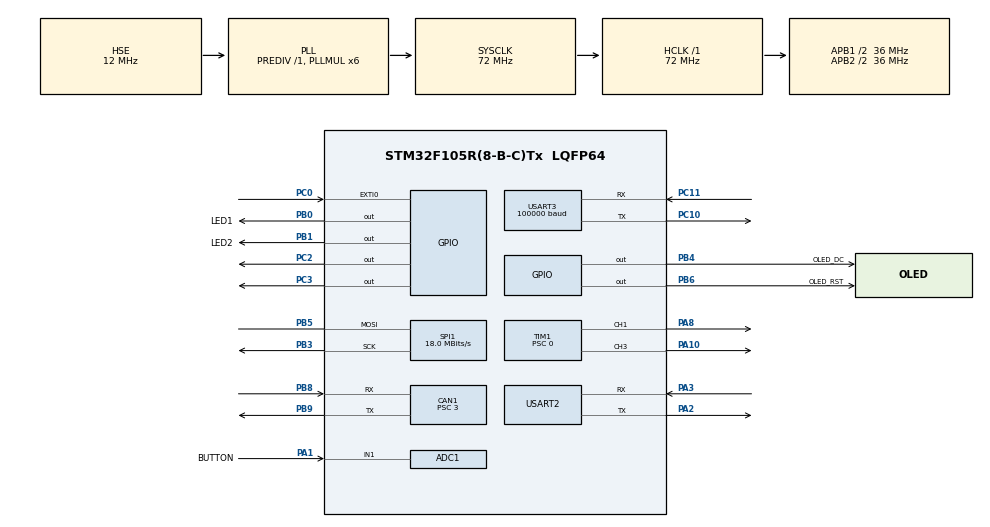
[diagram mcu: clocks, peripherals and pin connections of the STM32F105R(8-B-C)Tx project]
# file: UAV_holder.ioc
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Mcu.Family=STM32F1
NVIC.USART3_IRQn=true\:6\:0\:true\:true\:true\:1\:true\:true\:true
Dma.USART3_RX.1.Mode=DMA_CIRCULAR
SPI1.VirtualType=VM_MASTER
Dma.TIM1_CH3.3.MemDataAlignment=DMA_MDATAALIGN_HALFWORD
PC10.Signal=USART3_TX
PB0.GPIO_Label=LED1
PB6.GPIO_Label=OLED_RST
PC2.GPIO_Speed=GPIO_SPEED_FREQ_HIGH
Dma.TIM1_CH3.3.Direction=DMA_MEMORY_TO_PERIPH
PC3.GPIO_Speed=GPIO_SPEED_FREQ_HIGH
RCC.SYSCLKSource=RCC_SYSCLKSOURCE_PLLCLK
ProjectManager.StackSize=0x400
PC3.PinState=GPIO_PIN_SET
PD1-OSC_OUT.Signal=RCC_OSC_OUT
NVIC.DMA1_Channel3_IRQn=true\:6\:0\:true\:false\:true\:true\:false\:true
TIM1.Prescaler=0
Dma.USART3_RX.1.MemInc=DMA_MINC_ENABLE
USART3.BaudRate=100000
Dma.TIM1_CH1.2.Direction=DMA_MEMORY_TO_PERIPH
Dma.USART3_RX.1.Instance=DMA1_Channel3
PB0.PinState=GPIO_PIN_SET
NVIC.CAN1_TX_IRQn=true\:6\:0\:true\:false\:true\:true\:true\:true
FREERTOS.configUSE_STATS_FORMATTING_FUNCTIONS=1
SPI1.Direction=SPI_DIRECTION_1LINE
RCC.HCLKFreq_Value=72000000
RCC.APB2TimFreq_Value=72000000
PB6.Signal=GPIO_Output
Dma.ADC1.0.Direction=DMA_PERIPH_TO_MEMORY
Dma.USART3_RX.1.PeriphDataAlignment=DMA_PDATAALIGN_BYTE
SPI1.CalculateBaudRate=18.0 MBits/s
PC3.Signal=GPIO_Output
Dma.ADC1.0.MemDataAlignment=DMA_MDATAALIGN_HALFWORD
RCC.AHBFreq_Value=72000000
ADC1.Channel-0\#ChannelRegularConversion=ADC_CHANNEL_1
RCC.HSE_VALUE=12000000
PB3.Mode=Simplex_Bidirectional_Master
RCC.PLLMUL=RCC_PLL_MUL6
Dma.TIM1_CH3.3.Mode=DMA_NORMAL
Dma.USART3_RX.1.Priority=DMA_PRIORITY_LOW
TIM1.Channel-PWM\ Generation1\ CH1=TIM_CHANNEL_1
PA14.Mode=Serial_Wire
Dma.TIM1_CH1.2.Mode=DMA_NORMAL
Dma.ADC1.0.PeriphInc=DMA_PINC_DISABLE
PB1.GPIO_Label=LED2
PB5.Mode=Simplex_Bidirectional_Master
PA8.Signal=S_TIM1_CH1
TIM6.Period=65535
VP_FREERTOS_VS_CMSIS_V1.Mode=CMSIS_V1
ADC1.SamplingTime-0\#ChannelRegularConversion=ADC_SAMPLETIME_1CYCLE_5
PB1.PinState=GPIO_PIN_SET
CAN1.Prescaler=3
PB9.Signal=CAN1_TX
Mcu.Package=LQFP64
PB1.Signal=GPIO_Output
NVIC.TimeBase=TIM7_IRQn
USART2.VirtualMode=VM_ASYNC
Dma.USART3_RX.1.Direction=DMA_PERIPH_TO_MEMORY
NVIC.TimeBaseIP=TIM7
PA10.Signal=S_TIM1_CH3
PC11.Mode=Asynchronous
RCC.APB2CLKDivider=RCC_HCLK_DIV2
SH.ADCx_IN1.0=ADC1_IN1,IN1
Dma.Request2=TIM1_CH1
Dma.Request1=USART3_RX
RCC.APB1TimFreq_Value=72000000
FREERTOS.configGENERATE_RUN_TIME_STATS=1
Dma.Request3=TIM1_CH3
TIM1.Period=90-1
Dma.Request0=ADC1
CAN1.CalculateTimeBit=999.99
Dma.TIM1_CH1.2.Priority=DMA_PRIORITY_LOW
NVIC.TIM7_IRQn=true\:0\:0\:false\:false\:true\:false\:false\:true
Dma.TIM1_CH1.2.MemInc=DMA_MINC_ENABLE
Dma.TIM1_CH1.2.PeriphDataAlignment=DMA_PDATAALIGN_HALFWORD
PB4.Signal=GPIO_Output
PA3.Signal=USART2_RX
CAN1.CalculateTimeQuantum=83.33333333333334
RCC.PLLSourceVirtual=RCC_PLLSOURCE_HSE
NVIC.DMA1_Channel6_IRQn=true\:5\:0\:false\:false\:true\:true\:false\:true
Dma.TIM1_CH3.3.Priority=DMA_PRIORITY_LOW
Dma.ADC1.0.Instance=DMA1_Channel1
FREERTOS.Tasks01=defaultTask,0,128,StartDefaultTask,Default,NULL
ADC1.Rank-0\#ChannelRegularConversion=1
PD1-OSC_OUT.Mode=HSE-External-Oscillator
Dma.TIM1_CH1.2.PeriphInc=DMA_PINC_DISABLE
PC11.Signal=USART3_RX
VP_SYS_VS_tim7.Mode=TIM7
CAN1.CalculateBaudRate=1000000
TIM6.Prescaler=72-1
PC2.Signal=GPIO_Output
PC10.Mode=Asynchronous
VP_TIM6_VS_ClockSourceINT.Mode=Enable_Timer
Dma.USART3_RX.1.MemDataAlignment=DMA_MDATAALIGN_BYTE
PD0-OSC_IN.Signal=RCC_OSC_IN
Dma.TIM1_CH1.2.MemDataAlignment=DMA_MDATAALIGN_HALFWORD
PC0.Signal=GPXTI0
RCC.APB1CLKDivider=RCC_HCLK_DIV2
NVIC.TIM6_IRQn=true\:6\:0\:true\:false\:true\:true\:true\:true
RCC.ADCPresc=RCC_ADCPCLK2_DIV4
Dma.TIM1_CH1.2.Instance=DMA1_Channel2
PA13.Signal=SYS_JTMS-SWDIO
PA3.Mode=Asynchronous
Dma.ADC1.0.PeriphDataAlignment=DMA_PDATAALIGN_HALFWORD
Dma.TIM1_CH3.3.PeriphInc=DMA_PINC_DISABLE
SH.S_TIM1_CH1.0=TIM1_CH1,PWM Generation1 CH1
CAN1.BS2=CAN_BS2_4TQ
CAN1.BS1=CAN_BS1_7TQ
NVIC.DMA1_Channel2_IRQn=true\:5\:0\:false\:false\:true\:true\:false\:true
ProjectManager.TargetToolchain=MDK-ARM V5
FREERTOS.configUSE_TRACE_FACILITY=1
Dma.ADC1.0.Mode=DMA_NORMAL
PB9.Mode=CAN_Activate
Dma.ADC1.0.Priority=DMA_PRIORITY_LOW
Dma.TIM1_CH3.3.MemInc=DMA_MINC_ENABLE
RCC.USBFreq_Value=48000000
PA1.Signal=ADCx_IN1
PD0-OSC_IN.Mode=HSE-External-Oscillator
board=custom
RCC.APB2Freq_Value=36000000
PB4.GPIO_Label=OLED_DC
SPI1.Mode=SPI_MODE_MASTER
Dma.TIM1_CH3.3.Instance=DMA1_Channel6
PA1.GPIO_Label=BUTTON
PC2.GPIO_PuPd=GPIO_PULLUP
PA13.Mode=Serial_Wire
Mcu.Name=STM32F105R(8-B-C)Tx
PA2.Signal=USART2_TX
PB3.Signal=SPI1_SCK
RCC.SYSCLKFreq_VALUE=72000000
PB5.Signal=SPI1_MOSI
ADC1.master=1
PC2.PinState=GPIO_PIN_SET
USART3.VirtualMode=VM_ASYNC
PA14.Signal=SYS_JTCK-SWCLK
Dma.ADC1.0.MemInc=DMA_MINC_ENABLE
ProjectManager.HeapSize=0x200
SH.S_TIM1_CH3.0=TIM1_CH3,PWM Generation3 CH3
NVIC.PriorityGroup=NVIC_PRIORITYGROUP_4
ADC1.NbrOfConversionFlag=1
PB8.Mode=CAN_Activate
PB8.Signal=CAN1_RX
PA2.Mode=Asynchronous
Dma.TIM1_CH3.3.PeriphDataAlignment=DMA_PDATAALIGN_HALFWORD
NVIC.DMA1_Channel1_IRQn=true\:6\:0\:true\:false\:true\:true\:false\:true
TIM1.Channel-PWM\ Generation3\ CH3=TIM_CHANNEL_3
RCC.APB1Freq_Value=36000000
PB0.Signal=GPIO_Output
NVIC.CAN1_RX0_IRQn=true\:6\:0\:true\:false\:true\:true\:true\:true
Dma.USART3_RX.1.PeriphInc=DMA_PINC_DISABLE
PC3.GPIO_PuPd=GPIO_PULLUP

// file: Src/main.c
/* USER CODE BEGIN Header */
/**
  ******************************************************************************
  * @file           : main.c
  * @brief          : Main program body
  ******************************************************************************
  * @attention
  *
  * <h2><center>&copy; Copyright (c) 2019 STMicroelectronics.
  * All rights reserved.</center></h2>
  *
  * This software component is licensed by ST under Ultimate Liberty license
  * SLA0044, the "License"; You may not use this file except in compliance with
  * the License. You may obtain a copy of the License at:
  *                             www.st.com/SLA0044
  *
  ******************************************************************************
  */
/* USER CODE END Header */
#include "main.h"
#include "cmsis_os.h"
#include "adc.h"
#include "can.h"
#include "dma.h"
#include "spi.h"
#include "tim.h"
#include "usart.h"
#include "gpio.h"

/* USER CODE BEGIN Includes */
#include "bsp_can.h"
#include "Remote_Control.h"
#include "pid.h"
#include "Init.h"

/* USER CODE END Includes */

void SystemClock_Config(void);
void MX_FREERTOS_Init(void);
static void MX_NVIC_Init(void);

int main(void)
{

  /* MCU Configuration--------------------------------------------------------*/

  /* Reset of all peripherals, Initializes the Flash interface and the Systick. */
  HAL_Init();

  /* USER CODE BEGIN Init */
//extern volatile unsigned long long FreeRTOSRunTimeTicks;
  /* USER CODE END Init */

  /* Configure the system clock */
  SystemClock_Config();

  /* Initialize all configured peripherals */
  MX_GPIO_Init();
  MX_DMA_Init();
  MX_USART2_UART_Init();
  MX_ADC1_Init();
  MX_SPI1_Init();
  MX_USART3_UART_Init();
  MX_CAN1_Init();
  MX_TIM6_Init();
  MX_TIM1_Init();

  /* Initialize interrupts */
  MX_NVIC_Init();
  /* USER CODE BEGIN 2 */
	 User_Init();
	 Task_Init();
  /* USER CODE END 2 */

  /* Call init function for freertos objects (in freertos.c) */
  MX_FREERTOS_Init();
  /* Start scheduler */
  osKernelStart();

  /* We should never get here as control is now taken by the scheduler */
  /* Infinite loop */
  while (1)
  {

  }
}

void SystemClock_Config(void)
{
  RCC_OscInitTypeDef RCC_OscInitStruct = {0};
  RCC_ClkInitTypeDef RCC_ClkInitStruct = {0};
  RCC_PeriphCLKInitTypeDef PeriphClkInit = {0};

  /** Initializes the RCC Oscillators according to the specified parameters
  * in the RCC_OscInitTypeDef structure.
  */
  RCC_OscInitStruct.OscillatorType = RCC_OSCILLATORTYPE_HSE;
  RCC_OscInitStruct.HSEState = RCC_HSE_ON;
  RCC_OscInitStruct.HSEPredivValue = RCC_HSE_PREDIV_DIV1;
  RCC_OscInitStruct.HSIState = RCC_HSI_ON;
  RCC_OscInitStruct.Prediv1Source = RCC_PREDIV1_SOURCE_HSE;
  RCC_OscInitStruct.PLL.PLLState = RCC_PLL_ON;
  RCC_OscInitStruct.PLL.PLLSource = RCC_PLLSOURCE_HSE;
  RCC_OscInitStruct.PLL.PLLMUL = RCC_PLL_MUL6;
  RCC_OscInitStruct.PLL2.PLL2State = RCC_PLL_NONE;
  if (HAL_RCC_OscConfig(&RCC_OscInitStruct) != HAL_OK)
  {
    Error_Handler();
  }
  /** Initializes the CPU, AHB and APB buses clocks
  */
  RCC_ClkInitStruct.ClockType = RCC_CLOCKTYPE_HCLK|RCC_CLOCKTYPE_SYSCLK
                              |RCC_CLOCKTYPE_PCLK1|RCC_CLOCKTYPE_PCLK2;
  RCC_ClkInitStruct.SYSCLKSource = RCC_SYSCLKSOURCE_PLLCLK;
  RCC_ClkInitStruct.AHBCLKDivider = RCC_SYSCLK_DIV1;
  RCC_ClkInitStruct.APB1CLKDivider = RCC_HCLK_DIV2;
  RCC_ClkInitStruct.APB2CLKDivider = RCC_HCLK_DIV2;

  if (HAL_RCC_ClockConfig(&RCC_ClkInitStruct, FLASH_LATENCY_2) != HAL_OK)
  {
    Error_Handler();
  }
  PeriphClkInit.PeriphClockSelection = RCC_PERIPHCLK_ADC;
  PeriphClkInit.AdcClockSelection = RCC_ADCPCLK2_DIV4;
  if (HAL_RCCEx_PeriphCLKConfig(&PeriphClkInit) != HAL_OK)
  {
    Error_Handler();
  }
  /** Configure the Systick interrupt time
  */
  __HAL_RCC_PLLI2S_ENABLE();
}

/**
  * @brief NVIC Configuration.
  * @retval None
  */
static void MX_NVIC_Init(void)
{
  /* USART3_IRQn interrupt configuration */
  HAL_NVIC_SetPriority(USART3_IRQn, 6, 0);
  HAL_NVIC_EnableIRQ(USART3_IRQn);
}

/* USER CODE BEGIN 4 */
void vApplicationIdleHook(void)
{
//	uint16_t num;
//	num++;
//	printf("第%d次被调用",num);
}
/* USER CODE END 4 */

 /**
  * @brief  Period elapsed callback in non blocking mode
  * @note   This function is called  when TIM7 interrupt took place, inside
  * HAL_TIM_IRQHandler(). It makes a direct call to HAL_IncTick() to increment
  * a global variable "uwTick" used as application time base.
  * @param  htim : TIM handle
  * @retval None
  */
void HAL_TIM_PeriodElapsedCallback(TIM_HandleTypeDef *htim)
{
  if (htim->Instance == TIM7) {
    HAL_IncTick();
  }
}

void Error_Handler(void)
{
}

/************************ (C) COPYRIGHT STMicroelectronics *****END OF FILE****/

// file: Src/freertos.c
/* USER CODE BEGIN Header */
/**
  ******************************************************************************
  * File Name          : freertos.c
  * Description        : Code for freertos applications
  ******************************************************************************
  * @attention
  *
  * <h2><center>&copy; Copyright (c) 2019 STMicroelectronics.
  * All rights reserved.</center></h2>
  *
  * This software component is licensed by ST under Ultimate Liberty license
  * SLA0044, the "License"; You may not use this file except in compliance with
  * the License. You may obtain a copy of the License at:
  *                             www.st.com/SLA0044
  *
  ******************************************************************************
  */
/* USER CODE END Header */

#include "FreeRTOS.h"
#include "task.h"
#include "main.h"
#include "cmsis_os.h"

/* USER CODE BEGIN Variables */
//osThreadId motor_TaskHandle;
/* USER CODE END Variables */
osThreadId defaultTaskHandle;

void StartDefaultTask(void const * argument);

void MX_FREERTOS_Init(void); /* (MISRA C 2004 rule 8.1) */

/* GetIdleTaskMemory prototype (linked to static allocation support) */
void vApplicationGetIdleTaskMemory( StaticTask_t **ppxIdleTaskTCBBuffer, StackType_t **ppxIdleTaskStackBuffer, uint32_t *pulIdleTaskStackSize );

/* Hook prototypes */
void configureTimerForRunTimeStats(void);
unsigned long getRunTimeCounterValue(void);

/* USER CODE BEGIN 1 */
/* Functions needed when configGENERATE_RUN_TIME_STATS is on */
__weak void configureTimerForRunTimeStats(void)
{

}

__weak unsigned long getRunTimeCounterValue(void)
{
return 0;
}
/* USER CODE END 1 */

/* USER CODE BEGIN GET_IDLE_TASK_MEMORY */
static StaticTask_t xIdleTaskTCBBuffer;
static StackType_t xIdleStack[configMINIMAL_STACK_SIZE];

void vApplicationGetIdleTaskMemory( StaticTask_t **ppxIdleTaskTCBBuffer, StackType_t **ppxIdleTaskStackBuffer, uint32_t *pulIdleTaskStackSize )
{
  *ppxIdleTaskTCBBuffer = &xIdleTaskTCBBuffer;
  *ppxIdleTaskStackBuffer = &xIdleStack[0];
  *pulIdleTaskStackSize = configMINIMAL_STACK_SIZE;
  /* place for user code */
}
/* USER CODE END GET_IDLE_TASK_MEMORY */

void MX_FREERTOS_Init(void) {

  /* Create the thread(s) */
  /* definition and creation of defaultTask */
  osThreadDef(defaultTask, StartDefaultTask, osPriorityNormal, 0, 128);
  defaultTaskHandle = osThreadCreate(osThread(defaultTask), NULL);

}

void StartDefaultTask(void const * argument)
{
  for(;;)
	{
    osDelay(1);
  }
}

/************************ (C) COPYRIGHT STMicroelectronics *****END OF FILE****/
